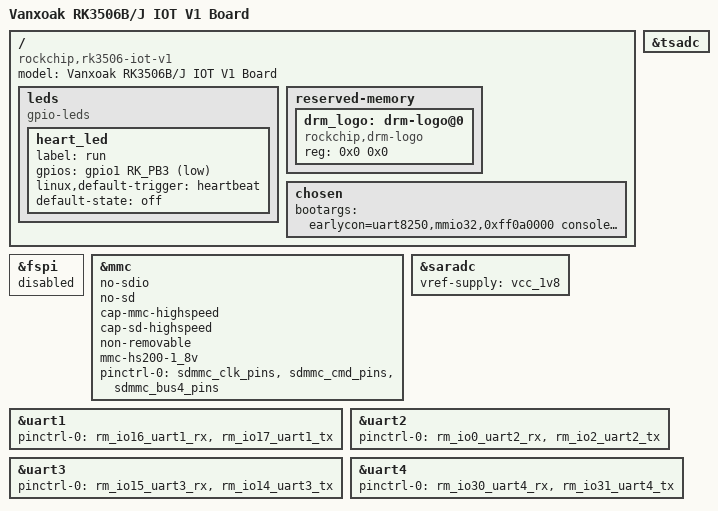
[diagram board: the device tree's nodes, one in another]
// SPDX-License-Identifier: (GPL-2.0+ OR MIT)
/*
 * Copyright (c) 2024 Rockchip Electronics Co., Ltd.
 */

/dts-v1/;

#include "rk3506.dtsi"
//#include "rk3502.dtsi"
#include "vanxoak-hd-rk3506-iot-v1.dtsi"
#include "vanxoak-hd-rk3506-iot-rgb-800x480.dtsi"

/ {
	model = "Vanxoak RK3506B/J IOT V1 Board";
	compatible = "rockchip,rk3506-iot-v1", "rockchip,rk3506";
	
		// LED
	leds {
		compatible = "gpio-leds";
		status = "okay";
		heart_led {
			label = "run";
			gpios = <&gpio1 RK_PB3 GPIO_ACTIVE_LOW>;
			linux,default-trigger = "heartbeat";
			default-state = "off";
		};
	};

	reserved-memory {
		#address-cells = <1>;
		#size-cells = <1>;
		ranges;


		drm_logo: drm-logo@0 {
			compatible = "rockchip,drm-logo";
			reg = <0x0 0x0>;
		};
	};

	chosen {
		bootargs = "earlycon=uart8250,mmio32,0xff0a0000 console=ttyFIQ0 root=PARTUUID=614e0000-0000 rw rootwait snd_aloop.index=7 snd_aloop.use_raw_jiffies=1";
	};
};

&fspi {
	status = "disabled";
};

&mmc {
	//For eMMC
	no-sdio;
	no-sd;
	cap-mmc-highspeed;
	cap-sd-highspeed;
	non-removable;
	mmc-hs200-1_8v;
	pinctrl-names = "default";
	pinctrl-0 = <&sdmmc_clk_pins &sdmmc_cmd_pins &sdmmc_bus4_pins>;
	status = "okay";
};

&tsadc {
	status = "okay";
};

&saradc {
	vref-supply = <&vcc_1v8>;
	status = "okay";
};

&uart1 {
	pinctrl-names = "default";
	pinctrl-0 = <&rm_io16_uart1_rx &rm_io17_uart1_tx>;
	status = "okay";
};

&uart2 {
	pinctrl-names = "default";
	pinctrl-0 = <&rm_io0_uart2_rx &rm_io2_uart2_tx>;
	status = "okay";
};

&uart3 {
	pinctrl-names = "default";
	pinctrl-0 = <&rm_io15_uart3_rx &rm_io14_uart3_tx>;
	status = "okay";
};

&uart4 {
	pinctrl-names = "default";
	pinctrl-0 = <&rm_io30_uart4_rx &rm_io31_uart4_tx>;
	status = "okay";
};





